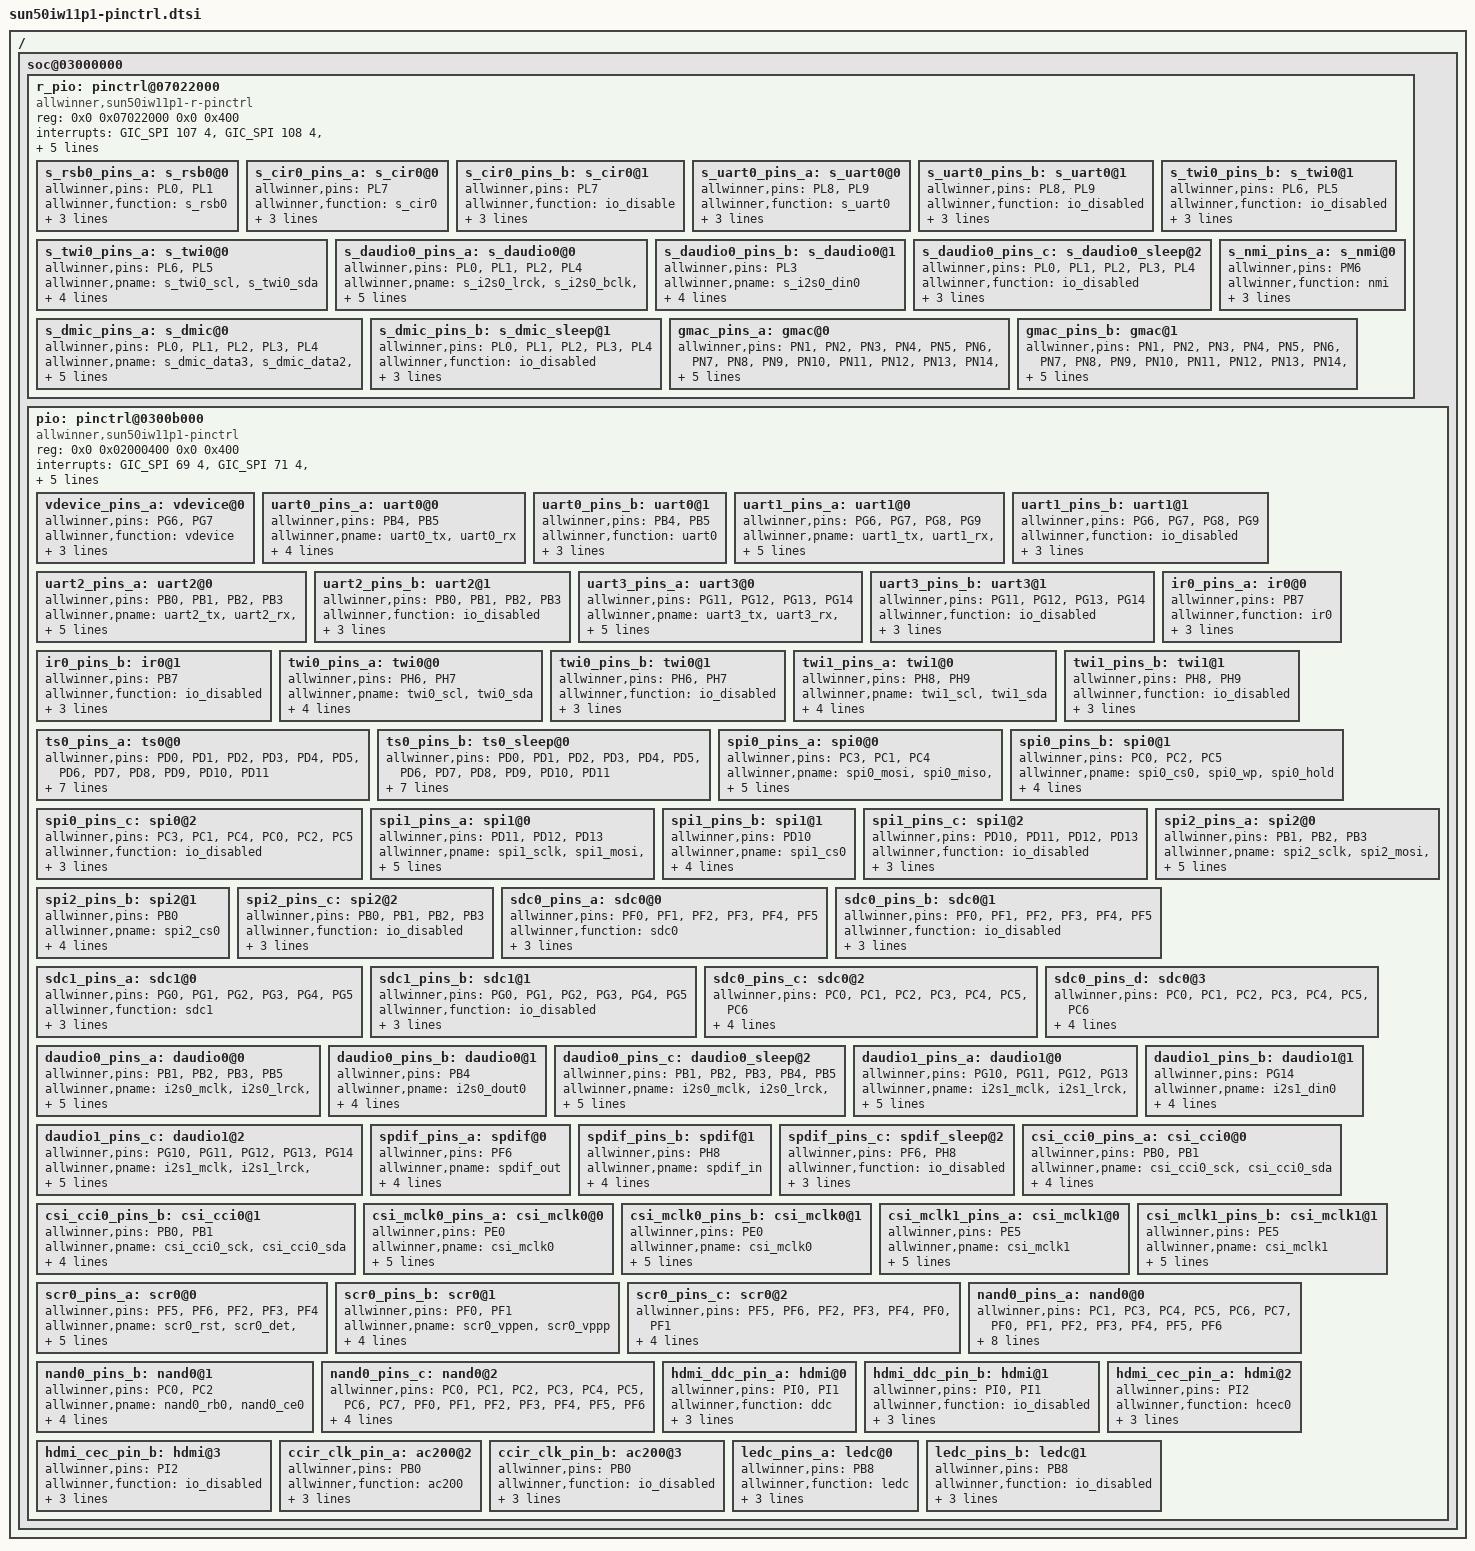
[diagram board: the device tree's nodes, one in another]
/*
 * Allwinner sun50iw11p1 pin config info.
 */

/ {
	soc@03000000{
		r_pio: pinctrl@07022000 {
			compatible = "allwinner,sun50iw11p1-r-pinctrl";
			reg = <0x0 0x07022000 0x0 0x400>;
			interrupts = <GIC_SPI 107 4>,
				     <GIC_SPI 108 4>,
				     <GIC_SPI 109 4>;
			clocks = <&clk_cpurpio>;
			device_type = "r_pio";
			gpio-controller;
			interrupt-controller;
			#interrupt-cells = <3>;
			#size-cells = <0>;
			#gpio-cells = <6>;
			input-debounce = <0 0 0>;

			s_rsb0_pins_a: s_rsb0@0 {
				allwinner,pins = "PL0", "PL1";
				allwinner,function = "s_rsb0";
				allwinner,muxsel = <2>;
				allwinner,drive = <2>;
				allwinner,pull = <1>;
			};

			s_cir0_pins_a: s_cir0@0 {
				allwinner,pins = "PL7";
				allwinner,function = "s_cir0";
				allwinner,muxsel = <2>;
				allwinner,drive = <1>;
				allwinner,pull = <1>;
			};

			s_cir0_pins_b: s_cir0@1 {
				allwinner,pins = "PL7";
				allwinner,function = "io_disable";
				allwinner,muxsel = <7>;
				allwinner,drive = <1>;
				allwinner,pull = <1>;
			};

			s_uart0_pins_a: s_uart0@0 {
				allwinner,pins = "PL8", "PL9";
				allwinner,function = "s_uart0";
				allwinner,muxsel = <2>;
				allwinner,drive = <1>;
				allwinner,pull = <1>;
			};

			s_uart0_pins_b: s_uart0@1 {
				allwinner,pins = "PL8", "PL9";
				allwinner,function = "io_disabled";  /* io_disabled */
				allwinner,muxsel = <7>;
				allwinner,drive = <1>;
				allwinner,pull = <1>;
			};

			s_twi0_pins_a: s_twi0@0 {
				allwinner,pins = "PL6", "PL5";
				allwinner,pname = "s_twi0_scl", "s_twi0_sda";
				allwinner,function = "s_twi0";
				allwinner,muxsel = <2>;
				allwinner,drive = <1>;
				allwinner,pull = <0>;
			};

			s_twi0_pins_b: s_twi0@1 {
				allwinner,pins = "PL6", "PL5";
				allwinner,function = "io_disabled";
				allwinner,muxsel = <7>;
				allwinner,drive = <1>;
				allwinner,pull = <0>;
			};

			s_daudio0_pins_a: s_daudio0@0 {
				allwinner,pins = "PL0", "PL1", "PL2", "PL4";
				allwinner,pname= "s_i2s0_lrck", "s_i2s0_bclk",
						"s_i2s0_dout0", "s_i2s0_mclk";
				allwinner,function = "s_i2s0";
				allwinner,muxsel = <2>;
				allwinner,drive = <1>;
				allwinner,pull = <0>;
			};

			s_daudio0_pins_b: s_daudio0@1 {
				allwinner,pins = "PL3";
				allwinner,pname = "s_i2s0_din0";
				allwinner,function = "s_i2s0";
				allwinner,muxsel = <3>;
				allwinner,drive = <1>;
				allwinner,pull = <0>;
			};

			s_daudio0_pins_c: s_daudio0_sleep@2 {
				allwinner,pins = "PL0", "PL1", "PL2", "PL3", "PL4";
				allwinner,function = "io_disabled";
				allwinner,muxsel = <7>;
				allwinner,drive = <1>;
				allwinner,pull = <0>;
			};

			s_dmic_pins_a: s_dmic@0 {
				allwinner,pins = "PL0", "PL1", "PL2", "PL3", "PL4";
				allwinner,pname= "s_dmic_data3", "s_dmic_data2",
						"s_dmic_data2", "s_dmic_data1",
						"s_dmic_clk";
				allwinner,function = "s_dmic";
				allwinner,muxsel = <4>;
				allwinner,drive = <1>;
				allwinner,pull = <0>;
			};

			s_dmic_pins_b: s_dmic_sleep@1 {
				allwinner,pins = "PL0", "PL1", "PL2", "PL3", "PL4";
				allwinner,function = "io_disabled";
				allwinner,muxsel = <7>;
				allwinner,drive = <1>;
				allwinner,pull = <0>;
			};

			s_nmi_pins_a: s_nmi@0 {
				allwinner,pins = "PM6";
				allwinner,function = "nmi";
				allwinner,muxsel = <2>;
				allwinner,drive = <1>;
				allwinner,pull = <1>;
			};

			gmac_pins_a: gmac@0 {
				allwinner,pins = "PN1", "PN2", "PN3", "PN4",
						 "PN5", "PN6", "PN7", "PN8",
						 "PN9", "PN10", "PN11", "PN12",
						 "PN13", "PN14", "PN15", "PN16",
						 "PN17";
				allwinner,function = "gmac0";
				allwinner,muxsel = <3>;
				allwinner,drive = <3>;
				allwinner,pull = <0>;
			};

			gmac_pins_b: gmac@1 {
				allwinner,pins = "PN1", "PN2", "PN3", "PN4",
						 "PN5", "PN6", "PN7", "PN8",
						 "PN9", "PN10", "PN11", "PN12",
						 "PN13", "PN14", "PN15", "PN16",
						 "PN17";
				allwinner,function = "io_disabled";
				allwinner,muxsel = <7>;
				allwinner,drive = <3>;
				allwinner,pull = <0>;
			};

		};

		pio: pinctrl@0300b000 {
			compatible = "allwinner,sun50iw11p1-pinctrl";
			reg = <0x0 0x02000400 0x0 0x400>;
			interrupts = <GIC_SPI 69 4>,  /* AW1851_GIC_Spec: GPIOB: 101-32=69 */
				     <GIC_SPI 71 4>,
				     <GIC_SPI 72 4>,
				     <GIC_SPI 73 4>;
			device_type = "pio";
			clocks = <&clk_pio>;
			gpio-controller;
			interrupt-controller;
			#interrupt-cells = <3>;
			#size-cells = <0>;
			#gpio-cells = <6>;
			/* takes the debounce time in usec as argument */
			input-debounce = <0 0 0 0 0>;

			vdevice_pins_a: vdevice@0 {
				allwinner,pins = "PG6", "PG7";
				allwinner,function = "vdevice";
				allwinner,muxsel = <5>;
				allwinner,drive = <1>;
				allwinner,pull = <1>;
			};
			/* FPGA stage: PB8 PB9, IC stage: PB4 PB5*/
			uart0_pins_a: uart0@0 {
				allwinner,pins = "PB4", "PB5";
				allwinner,pname = "uart0_tx", "uart0_rx";
				allwinner,function = "uart0";
				allwinner,muxsel = <2>;
				allwinner,drive = <1>;
				allwinner,pull = <1>;
			};

			uart0_pins_b: uart0@1 {
				allwinner,pins = "PB4", "PB5";
				allwinner,function = "uart0";  /* io_disabled */
				allwinner,muxsel = <7>;
				allwinner,drive = <1>;
				allwinner,pull = <0>;
			};

			uart1_pins_a: uart1@0 {
				allwinner,pins = "PG6", "PG7", "PG8", "PG9";
				allwinner,pname = "uart1_tx", "uart1_rx",
						  "uart1_rts", "uart1_cts";
				allwinner,function = "uart1";
				allwinner,muxsel = <2>;
				allwinner,drive = <1>;
				allwinner,pull = <1>;
			};

			uart1_pins_b: uart1@1 {
				allwinner,pins = "PG6", "PG7", "PG8", "PG9";
				allwinner,function = "io_disabled";
				allwinner,muxsel = <7>;
				allwinner,drive = <1>;
				allwinner,pull = <0>;
			};

			uart2_pins_a: uart2@0 {
				allwinner,pins = "PB0", "PB1", "PB2", "PB3";
				allwinner,pname = "uart2_tx", "uart2_rx",
						  "uart2_rts", "uart2_cts";
				allwinner,function = "uart2";
				allwinner,muxsel = <2>;
				allwinner,drive = <1>;
				allwinner,pull = <1>;
			};

			uart2_pins_b: uart2@1 {
				allwinner,pins = "PB0", "PB1", "PB2", "PB3";
				allwinner,function = "io_disabled";
				allwinner,muxsel = <7>;
				allwinner,drive = <1>;
				allwinner,pull = <0>;
			};

			uart3_pins_a: uart3@0 {
				allwinner,pins = "PG11", "PG12", "PG13", "PG14";
				allwinner,pname = "uart3_tx", "uart3_rx",
						  "uart3_rts", "uart3_cts";
				allwinner,function = "uart3";
				allwinner,muxsel = <2>;
				allwinner,drive = <1>;
				allwinner,pull = <1>;
			};

			uart3_pins_b: uart3@1 {
				allwinner,pins = "PG11", "PG12", "PG13", "PG14";
				allwinner,function = "io_disabled";
				allwinner,muxsel = <7>;
				allwinner,drive = <1>;
				allwinner,pull = <0>;
			};

			ir0_pins_a: ir0@0 {
				allwinner,pins = "PB7";
				allwinner,function = "ir0";
				allwinner,muxsel = <2>;
				allwinner,drive = <2>;
				allwinner,pull = <1>;
			};

			ir0_pins_b: ir0@1 {
				allwinner,pins = "PB7";
				allwinner,function = "io_disabled";
				allwinner,muxsel = <7>;
				allwinner,drive = <2>;
				allwinner,pull = <1>;
			};

			twi0_pins_a: twi0@0 {
				allwinner,pins = "PH6", "PH7";
				allwinner,pname = "twi0_scl", "twi0_sda";
				allwinner,function = "twi0";
				allwinner,muxsel = <4>;
				allwinner,drive = <1>;
				allwinner,pull = <1>;
			};

			twi0_pins_b: twi0@1 {
				allwinner,pins = "PH6", "PH7";
				allwinner,function = "io_disabled";
				allwinner,muxsel = <7>;
				allwinner,drive = <1>;
				allwinner,pull = <1>;
			};

			twi1_pins_a: twi1@0 {
				allwinner,pins = "PH8", "PH9";
				allwinner,pname = "twi1_scl", "twi1_sda";
				allwinner,function = "twi1";
				allwinner,muxsel = <2>;
				allwinner,drive = <1>;
				allwinner,pull = <0>;
			};

			twi1_pins_b: twi1@1 {
				allwinner,pins = "PH8", "PH9";
				allwinner,function = "io_disabled";
				allwinner,muxsel = <7>;
				allwinner,drive = <1>;
				allwinner,pull = <0>;
			};

			ts0_pins_a: ts0@0 {
				allwinner,pins = "PD0", "PD1", "PD2", "PD3",
						 "PD4", "PD5", "PD6", "PD7",
						 "PD8", "PD9", "PD10", "PD11";
				allwinner,pname = "ts0_clk", "ts0_err",
						  "ts0_sync", "ts0_dvld",
						  "ts0_d0", "ts0_d1",
						  "ts0_d2", "ts0_d3",
						  "ts0_d4", "ts0_d5",
						  "ts0_d6", "ts0_d7";
				allwinner,function = "ts0";
				allwinner,muxsel = <4>;
				allwinner,drive = <1>;
				allwinner,pull = <0>;
			};

			ts0_pins_b: ts0_sleep@0 {
				allwinner,pins = "PD0", "PD1", "PD2", "PD3",
						 "PD4", "PD5", "PD6", "PD7",
						 "PD8", "PD9", "PD10", "PD11";
				allwinner,pname = "ts0_clk", "ts0_err",
						  "ts0_sync", "ts0_dvld",
						  "ts0_d0", "ts0_d1",
						  "ts0_d2", "ts0_d3",
						  "ts0_d4", "ts0_d5",
						  "ts0_d6", "ts0_d7";
				allwinner,function = "io_disabled";
				allwinner,muxsel = <7>;
				allwinner,drive = <1>;
				allwinner,pull = <0>;
			};

			spi0_pins_a: spi0@0 {
				allwinner,pins = "PC3", "PC1", "PC4";
				allwinner,pname = "spi0_mosi", "spi0_miso", "spi0_sclk";
				allwinner,function = "spi0";
				allwinner,muxsel = <4>;
				allwinner,drive = <2>;
				allwinner,pull = <0>;
			};

			spi0_pins_b: spi0@1 {
				allwinner,pins = "PC0", "PC2", "PC5";
				allwinner,pname = "spi0_cs0", "spi0_wp", "spi0_hold";
				allwinner,function = "spi0";
				allwinner,muxsel = <4>;
				allwinner,drive = <2>;
				allwinner,pull = <1>;	/* CS, WP and HOLD should be pulled up */
			};

			spi0_pins_c: spi0@2 {
				allwinner,pins = "PC3", "PC1", "PC4", "PC0", "PC2", "PC5";
				allwinner,function = "io_disabled";
				allwinner,muxsel = <7>;
				allwinner,drive = <2>;
				allwinner,pull = <0>;
			};

			spi1_pins_a: spi1@0 {
				allwinner,pins = "PD11", "PD12", "PD13";
				allwinner,pname = "spi1_sclk", "spi1_mosi",
						  "spi1_miso";
				allwinner,function = "spi1";
				allwinner,muxsel = <4>;
				allwinner,drive = <1>;
				allwinner,pull = <0>;
			};

			spi1_pins_b: spi1@1 {
				allwinner,pins = "PD10";
				allwinner,pname = "spi1_cs0";
				allwinner,function = "spi1";
				allwinner,muxsel = <4>;
				allwinner,drive = <1>;
				allwinner,pull = <1>;	/* only CS should be pulled up */
			};

			spi1_pins_c: spi1@2 {
				allwinner,pins = "PD10", "PD11", "PD12", "PD13";
				allwinner,function = "io_disabled";
				allwinner,muxsel = <7>;
				allwinner,drive = <1>;
				allwinner,pull = <0>;
			};

			spi2_pins_a: spi2@0 {
				allwinner,pins = "PB1", "PB2", "PB3";
				allwinner,pname = "spi2_sclk", "spi2_mosi",
						  "spi2_miso";
				allwinner,function = "spi2";
				allwinner,muxsel = <3>;
				allwinner,drive = <1>;
				allwinner,pull = <0>;
			};

			spi2_pins_b: spi2@1 {
				allwinner,pins = "PB0";
				allwinner,pname = "spi2_cs0";
				allwinner,function = "spi2";
				allwinner,muxsel = <3>;
				allwinner,drive = <1>;
				allwinner,pull = <1>;	/* only CS should be pulled up */
			};

			spi2_pins_c: spi2@2 {
				allwinner,pins = "PB0", "PB1", "PB2", "PB3";
				allwinner,function = "io_disabled";
				allwinner,muxsel = <7>;
				allwinner,drive = <1>;
				allwinner,pull = <0>;
			};

			sdc0_pins_a: sdc0@0 {
				allwinner,pins = "PF0", "PF1", "PF2",
						 "PF3", "PF4", "PF5";
				allwinner,function = "sdc0";
				allwinner,muxsel = <5>;
				allwinner,drive = <1>;
				allwinner,pull = <1>;
			};

			sdc0_pins_b: sdc0@1 {
				allwinner,pins = "PF0", "PF1", "PF2",
						 "PF3", "PF4", "PF5";
				allwinner,function = "io_disabled";
				allwinner,muxsel = <7>;
				allwinner,drive = <1>;
				allwinner,pull = <1>;
			};

			sdc1_pins_a: sdc1@0 {
				allwinner,pins = "PG0", "PG1", "PG2",
						 "PG3", "PG4", "PG5";
				allwinner,function = "sdc1";
				allwinner,muxsel = <4>;
				allwinner,drive = <3>;
				allwinner,pull = <1>;
			};

			sdc1_pins_b: sdc1@1 {
				allwinner,pins = "PG0", "PG1", "PG2",
						 "PG3", "PG4", "PG5";
				allwinner,function = "io_disabled";
				allwinner,muxsel = <7>;
				allwinner,drive = <1>;
				allwinner,pull = <1>;
			};

			sdc0_pins_c: sdc0@2 {
				allwinner,pins = "PC0", "PC1", "PC2", "PC3",
						 "PC4", "PC5", "PC6";
				allwinner,function = "sdc0";
				allwinner,muxsel = <3>;
				allwinner,drive = <2>;
				allwinner,pull = <1>;
			};

			sdc0_pins_d: sdc0@3 {
				allwinner,pins = "PC0", "PC1", "PC2", "PC3",
						 "PC4", "PC5", "PC6";
				allwinner,function = "io_disabled";
				allwinner,muxsel = <7>;
				allwinner,drive = <1>;
				allwinner,pull = <1>;
			};

			daudio0_pins_a: daudio0@0 {
				allwinner,pins = "PB1", "PB2", "PB3", "PB5";
				allwinner,pname= "i2s0_mclk", "i2s0_lrck",
						"i2s0_bclk", "i2s0_din0";
				allwinner,function = "i2s0";
				allwinner,muxsel = <5>;
				allwinner,drive = <1>;
				allwinner,pull = <0>;
			};

			daudio0_pins_b: daudio0@1 {
				allwinner,pins = "PB4";
				allwinner,pname= "i2s0_dout0";
				allwinner,function = "i2s0";
				allwinner,muxsel = <4>;
				allwinner,drive = <1>;
				allwinner,pull = <0>;
			};

			daudio0_pins_c: daudio0_sleep@2 {
				allwinner,pins = "PB1", "PB2", "PB3", "PB4", "PB5";
				allwinner,pname= "i2s0_mclk", "i2s0_lrck",
						"i2s0_bclk", "i2s0_dout0",
						"i2s0_din0";
				allwinner,function = "io_disabled";
				allwinner,muxsel = <7>;
				allwinner,drive = <1>;
				allwinner,pull = <0>;
			};

			daudio1_pins_a: daudio1@0 {
				allwinner,pins = "PG10", "PG11", "PG12", "PG13";
				allwinner,pname= "i2s1_mclk", "i2s1_lrck",
						"i2s1_bclk", "i2s1_dout0";
				allwinner,function = "i2s1";
				allwinner,muxsel = <3>;
				allwinner,drive = <1>;
				allwinner,pull = <0>;
			};

			daudio1_pins_b: daudio1@1 {
				allwinner,pins = "PG14";
				allwinner,pname= "i2s1_din0";
				allwinner,function = "i2s1";
				allwinner,muxsel = <4>;
				allwinner,drive = <1>;
				allwinner,pull = <0>;
			};

			daudio1_pins_c: daudio1@2 {
				allwinner,pins = "PG10", "PG11", "PG12", "PG13", "PG14";
				allwinner,pname= "i2s1_mclk", "i2s1_lrck",
						"i2s1_bclk", "i2s1_dout0",
						"i2s1_din0";
				allwinner,function = "io_disabled";
				allwinner,muxsel = <7>;
				allwinner,drive = <1>;
				allwinner,pull = <0>;
			};

			spdif_pins_a: spdif@0 {
				allwinner,pins = "PF6";
				allwinner,pname = "spdif_out";
				allwinner,function = "spdif_out";
				allwinner,muxsel = <5>;/*PF6 <4> spdif_in*/
				allwinner,drive = <1>;
				allwinner,pull = <0>;
			};

			spdif_pins_b: spdif@1 {
				allwinner,pins = "PH8";
				allwinner,pname = "spdif_in";
				allwinner,function = "spdif_in";
				allwinner,muxsel = <4>;
				allwinner,drive = <1>;
				allwinner,pull = <0>;
			};
			spdif_pins_c: spdif_sleep@2 {
				allwinner,pins = "PF6","PH8";
				allwinner,function = "io_disabled";
				allwinner,muxsel = <7>;
				allwinner,drive = <1>;
				allwinner,pull = <0>;
			};

			csi_cci0_pins_a: csi_cci0@0 {
				allwinner,pins = "PB0", "PB1";
				allwinner,pname = "csi_cci0_sck", "csi_cci0_sda";
				allwinner,function = "csi_cci0";
				allwinner,muxsel = <4>;
				allwinner,drive = <1>;
				allwinner,pull = <0>;
			};

			csi_cci0_pins_b: csi_cci0@1 {
				allwinner,pins = "PB0", "PB1";
				allwinner,pname = "csi_cci0_sck", "csi_cci0_sda";
				allwinner,function = "io_disabled";
				allwinner,muxsel = <7>;
				allwinner,drive = <1>;
				allwinner,pull = <0>;
			};

			csi_mclk0_pins_a: csi_mclk0@0 {
				allwinner,pins = "PE0";
				allwinner,pname = "csi_mclk0";
				allwinner,function = "csi_mclk0";
				allwinner,muxsel = <2>;
				allwinner,drive = <2>;
				allwinner,pull = <0>;
				allwinner,data = <0>;
			};
			csi_mclk0_pins_b: csi_mclk0@1 {
				allwinner,pins = "PE0";
				allwinner,pname = "csi_mclk0";
				allwinner,function = "io_disabled";
				allwinner,muxsel = <7>;
				allwinner,drive = <2>;
				allwinner,pull = <0>;
				allwinner,data = <0>;
			};
			csi_mclk1_pins_a: csi_mclk1@0 {
				allwinner,pins = "PE5";
				allwinner,pname = "csi_mclk1";
				allwinner,function = "csi_mclk1";
				allwinner,muxsel = <2>;
				allwinner,drive = <2>;
				allwinner,pull = <0>;
				allwinner,data = <0>;
			};
			csi_mclk1_pins_b: csi_mclk1@1 {
				allwinner,pins = "PE5";
				allwinner,pname = "csi_mclk1";
				allwinner,function = "io_disabled";
				allwinner,muxsel = <7>;
				allwinner,drive = <2>;
				allwinner,pull = <0>;
				allwinner,data = <0>;
			};

			scr0_pins_a: scr0@0 {
				allwinner,pins = "PF5", "PF6", "PF2", "PF3", "PF4";
				allwinner,pname = "scr0_rst", "scr0_det", "scr0_vccen", "scr0_sck", "scr0_sda";
				allwinner,function = "sim0";
				allwinner,muxsel = <3>;
				allwinner,drive = <0>;
				allwinner,pull = <1>;
			};

			scr0_pins_b: scr0@1 {
				allwinner,pins = "PF0", "PF1";
				allwinner,pname = "scr0_vppen", "scr0_vppp";
				allwinner,function = "sim0";
				allwinner,muxsel = <3>;
				allwinner,drive = <0>;
				allwinner,pull = <1>;
			};

			scr0_pins_c: scr0@2 {
				allwinner,pins = "PF5", "PF6", "PF2", "PF3", "PF4", "PF0", "PF1";
				allwinner,function = "io_disabled";
				allwinner,muxsel = <7>;
				allwinner,drive = <0>;
				allwinner,pull = <0>;
			};

			nand0_pins_a: nand0@0 {
				allwinner,pins = "PC1", "PC3", "PC4", "PC5",
						 "PC6", "PC7", "PF0", "PF1",
						 "PF2", "PF3", "PF4", "PF5",
						 "PF6";
				allwinner,pname= "nand0_re", "nand0_cle","nand0_ale", "nand0_we",
						 "nand0_d0", "nand0_d1", "nand0_d7", "nand0_d6",
						 "nand0_d5", "nand0_d4", "nand0_ndqs", "nand0_d3",
						 "nand0_d2";
				allwinner,function = "nand0";
				allwinner,muxsel = <2>;
				allwinner,drive = <1>;
				allwinner,pull = <0>;
			};

			nand0_pins_b: nand0@1 {
				allwinner,pins = "PC0", "PC2";
				allwinner,pname= "nand0_rb0", "nand0_ce0";
				allwinner,function = "nand0";
				allwinner,muxsel = <2>;
				allwinner,drive = <1>;
				allwinner,pull = <1>;	/* only RB&CE should be pulled up */
			};

			nand0_pins_c: nand0@2 {
				allwinner,pins = "PC0", "PC1", "PC2", "PC3",
						 "PC4", "PC5", "PC6", "PC7",
						 "PF0", "PF1", "PF2", "PF3",
						 "PF4", "PF5", "PF6";
				allwinner,function = "io_disabled";
				allwinner,muxsel = <7>;
				allwinner,drive = <1>;
				allwinner,pull = <0>;
			};

			hdmi_ddc_pin_a: hdmi@0 {
				allwinner,pins = "PI0","PI1";
				allwinner,function = "ddc";
				allwinner,muxsel = <5>;
				allwinner,drive = <1>;
				allwinner,pull = <0>;
			};

			hdmi_ddc_pin_b: hdmi@1 {
				allwinner,pins = "PI0","PI1";
				allwinner,function = "io_disabled";
				allwinner,muxsel = <7>;
				allwinner,drive = <1>;
				allwinner,pull = <0>;
			};

			hdmi_cec_pin_a: hdmi@2 {
				allwinner,pins = "PI2";
				allwinner,function = "hcec0";
				allwinner,muxsel = <5>;
				allwinner,drive = <1>;
				allwinner,pull = <0>;
			};

			hdmi_cec_pin_b: hdmi@3 {
				allwinner,pins = "PI2";
				allwinner,function = "io_disabled";
				allwinner,muxsel = <7>;
				allwinner,drive = <1>;
				allwinner,pull = <0>;
			};

			ccir_clk_pin_a: ac200@2 {
				allwinner,pins = "PB0";
				allwinner,function = "ac200";
				allwinner,muxsel = <2>;
				allwinner,drive = <1>;
				allwinner,pull = <0>;
			};

			ccir_clk_pin_b: ac200@3 {
				allwinner,pins = "PB0";
				allwinner,function = "io_disabled";
				allwinner,muxsel = <7>;
				allwinner,drive = <1>;
				allwinner,pull = <0>;
			};

			ledc_pins_a: ledc@0 {
				allwinner,pins = "PB8";
				allwinner,function = "ledc";
				allwinner,muxsel = <5>;
				allwinner,drive = <1>;
				allwinner,pull = <1>;
			};

			ledc_pins_b: ledc@1 {
				allwinner,pins = "PB8";
				allwinner,function = "io_disabled";
				allwinner,muxsel = <7>;
				allwinner,drive = <1>;
				allwinner,pull = <0>;
			};
		};
	};
};
